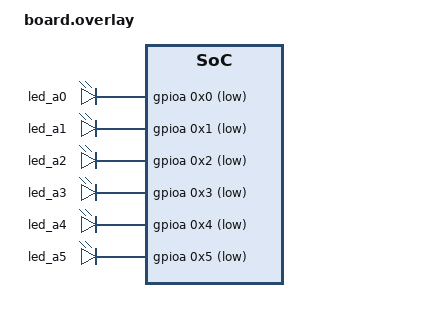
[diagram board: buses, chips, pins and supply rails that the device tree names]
/*
 * Copyright (c) 2021 Nordic Semiconductor ASA
 *
 * SPDX-License-Identifier: Apache-2.0
 */

/ {
    aliases {
        led-caps = &led_a3;
        led-num = &led_a4;
        led-scrl = &led_a5;
        led-a = &led_a0;
        led-b = &led_a1;
        led-c = &led_a2;
    };

    leds {
        compatible = "gpio-leds";
        // Define leds, additionally connected to this board
        // A0
        led_a0: led_a0 {
            gpios = < &gpioa 0x0 GPIO_ACTIVE_LOW >;
        };
        // A1
        led_a1: led_a1 {
            gpios = < &gpioa 0x1 GPIO_ACTIVE_LOW >;
        };
        // A2
        led_a2: led_a2 {
            gpios = < &gpioa 0x2 GPIO_ACTIVE_LOW >;
        };
        // A3
        led_a3: led_a3 {
            gpios = < &gpioa 0x3 GPIO_ACTIVE_LOW >;
        };
        // A4
        led_a4: led_a4 {
            gpios = < &gpioa 0x4 GPIO_ACTIVE_LOW >;
        };
        // A5
        led_a5: led_a5 {
            gpios = < &gpioa 0x5 GPIO_ACTIVE_LOW >;
        };
    };

};
